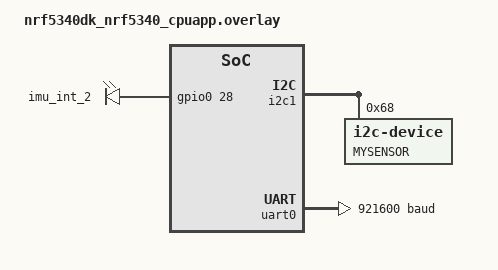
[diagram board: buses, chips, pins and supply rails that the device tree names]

&i2c1 {
    mysensor: mysensor@68 {
        compatible = "i2c-device";
        reg = <0x68>;
        label = "MYSENSOR";
    };
};

&uart0 {
	status = "okay";
	current-speed = <921600>; //<115200>;
};

/ {
    aliases {
        led1 = &led1;
    };

    imu_int_2 {
        compatible = "gpio-leds";
        imu_int_2:imu_int_2 {
            gpios = < &gpio0 28 GPIO_ACTIVE_HIGH>; 
            label = "imu_int_2";
        };
    };

};
